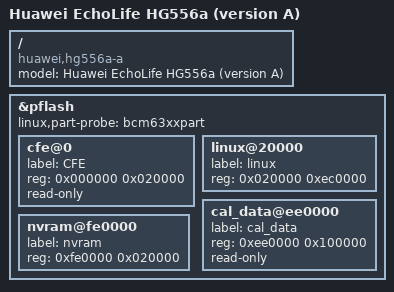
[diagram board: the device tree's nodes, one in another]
/dts-v1/;

/include/ "bcm6358.dtsi"

/ {
	model = "Huawei EchoLife HG556a (version A)";
	compatible = "huawei,hg556a-a", "brcm,bcm6358";
};

&pflash {
	status = "ok";

	linux,part-probe = "bcm63xxpart";

	cfe@0 {
		label = "CFE";
		reg = <0x000000 0x020000>;
		read-only;
	};

	linux@20000 {
		label = "linux";
		reg = <0x020000 0xec0000>;
	};

	cal_data@ee0000 {
		label = "cal_data";
		reg = <0xee0000 0x100000>;
		read-only;
	};

	nvram@fe0000 {
		label = "nvram";
		reg = <0xfe0000 0x020000>;
	};
};
